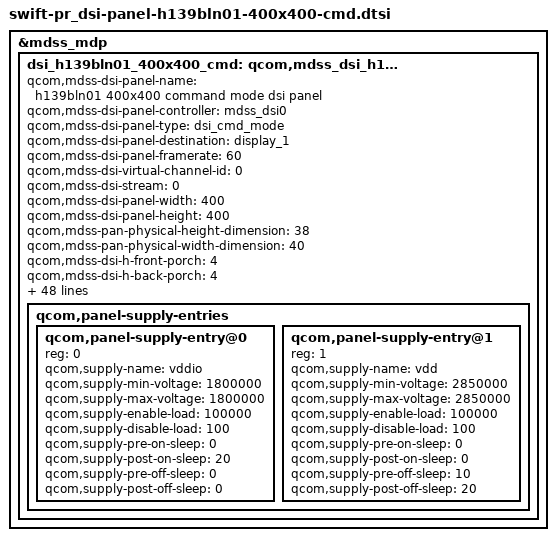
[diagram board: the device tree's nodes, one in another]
/* Copyright (c) 2013-2014, The Linux Foundation. All rights reserved.
 *
 * This program is free software; you can redistribute it and/or modify
 * it under the terms of the GNU General Public License version 2 and
 * only version 2 as published by the Free Software Foundation.
 *
 * This program is distributed in the hope that it will be useful,
 * but WITHOUT ANY WARRANTY; without even the implied warranty of
 * MERCHANTABILITY or FITNESS FOR A PARTICULAR PURPOSE.  See the
 * GNU General Public License for more details.
 */

/*---------------------------------------------------------------------------
 * This file is autogenerated file using gcdb parser. Please do not edit it.
 * Update input XML file to add a new entry or update variable in this file
 * VERSION = "1.0"
 *---------------------------------------------------------------------------*/
&mdss_mdp {
	dsi_h139bln01_400x400_cmd: qcom,mdss_dsi_h139bln01_400_cmd {
		qcom,mdss-dsi-panel-name = "h139bln01 400x400 command mode dsi panel";
		qcom,mdss-dsi-panel-controller = <&mdss_dsi0>;
		qcom,mdss-dsi-panel-type = "dsi_cmd_mode";
		qcom,mdss-dsi-panel-destination = "display_1";
		qcom,mdss-dsi-panel-framerate = <60>;
		qcom,mdss-dsi-virtual-channel-id = <0>;
		qcom,mdss-dsi-stream = <0>;
		qcom,mdss-dsi-panel-width = <400>;
		qcom,mdss-dsi-panel-height = <400>;
		qcom,mdss-pan-physical-height-dimension = <38>;
		qcom,mdss-pan-physical-width-dimension = <40>;

		qcom,mdss-dsi-h-front-porch = <4>;
		qcom,mdss-dsi-h-back-porch = <4>;
		qcom,mdss-dsi-h-pulse-width = <4>;
		qcom,mdss-dsi-h-sync-skew = <0>;
		qcom,mdss-dsi-v-back-porch = <2>;
		qcom,mdss-dsi-v-front-porch = <2>;
		qcom,mdss-dsi-v-pulse-width = <2>;
		qcom,mdss-dsi-h-left-border = <0>;
		qcom,mdss-dsi-h-right-border = <0>;
		qcom,mdss-dsi-v-top-border = <0>;
		qcom,mdss-dsi-v-bottom-border = <0>;
		qcom,mdss-dsi-bpp = <24>;
		qcom,mdss-dsi-underflow-color = <0xff>;
		qcom,mdss-dsi-border-color = <0>;
		qcom,mdss-dsi-on-command = [

			15 01 00 00 00 00 02 FE 00
			15 01 00 00 00 00 02 35 00
			15 01 00 00 00 00 02 53 20
			15 01 00 00 00 00 02 FE 05
			15 01 00 00 00 00 02 05 00
			15 01 00 00 00 00 02 FE 07
			15 01 00 00 00 00 02 07 4F
			15 01 00 00 00 00 02 FE 0A
			15 01 00 00 00 00 02 1C 1B
			15 01 00 00 00 00 02 FE 00
			15 01 00 00 00 00 02 35 00
			05 01 00 00 00 00 02 11 00
			32 01 00 00 00 00 02 00 00
			05 01 00 00 FF 00 02 29 00
			15 01 00 00 00 00 02 51 40

			];

		qcom,mdss-dsi-off-command = [
					05 01 00 00 00 00 02 28 00
					];

		qcom,mdss-dsi-sleep-command = [
			05 01 00 00 78 00 02 10 00
			];

		qcom,mdss-dsi-idle-on-command = [
					05 01 00 00 64 00 02 39 00
					];
		qcom,mdss-dsi-idle-off-command = [
					05 01 00 00 64 00 02 38 00
					];

		//qcom,mdss-dsi-panel-status-command = [06 01 00 01 05 00 02 0A 08];

		qcom,mdss-dsi-idle-command-state = "dsi_lp_mode";

		qcom,mdss-dsi-on-command-state = "dsi_lp_mode";
		qcom,mdss-dsi-off-command-state = "dsi_lp_mode";
		qcom,mdss-dsi-sleep-command-state = "dsi_lp_mode";
		qcom,mdss-dsi-bllp-eof-power-mode;
		qcom,mdss-dsi-bllp-power-mode;
		//qcom,mdss-dsi-lane-map = "lane_map_3012"; /* Eagle's lane map does not need to remap */
		qcom,mdss-dsi-lane-0-state;
		qcom,mdss-dsi-te-pin-select = <1>;
		qcom,mdss-dsi-te-dcs-command = <1>;
		qcom,mdss-dsi-te-check-enable;
		qcom,mdss-dsi-te-using-te-pin;
		qcom,suspend-ulps-enabled;
		qcom,ulps-enabled = <1>;

		/* By AUO's suggestion: MIPI Clock rate = ~290Mbps. */
		qcom,mdss-dsi-panel-timings = [38 0C 08 00 64 64 0C 19 08 03 04 00];

		qcom,mdss-dsi-t-clk-post = <0x04>;
		qcom,mdss-dsi-t-clk-pre = <0x1b>;
		qcom,mdss-dsi-bl-min-level = <1>;
		qcom,mdss-dsi-bl-max-level = <255>;
		qcom,mdss-dsi-dma-trigger = "trigger_sw";
		qcom,mdss-dsi-mdp-trigger = "none";
		qcom,mdss-dsi-bl-pmic-control-type = "bl_ctrl_dcs";
		qcom,mdss-dsi-reset-sequence = <1 20>;

		/* this codebase retrieve panel power from panel node */
		vdd-supply = <&pm8916_l17>;
		vddio-supply = <&pm8916_l15>;
		qcom,panel-supply-entries {
			#address-cells = <1>;
			#size-cells = <0>;

			qcom,panel-supply-entry@0 {
				reg = <0>;
				qcom,supply-name = "vddio";
				qcom,supply-min-voltage = <1800000>;
				qcom,supply-max-voltage = <1800000>;
				qcom,supply-enable-load = <100000>;
				qcom,supply-disable-load = <100>;
				qcom,supply-pre-on-sleep = <0>;
				qcom,supply-post-on-sleep = <20>;
				qcom,supply-pre-off-sleep = <0>;
				qcom,supply-post-off-sleep = <0>;
			};

			qcom,panel-supply-entry@1 {
				reg = <1>;
				qcom,supply-name = "vdd";
				qcom,supply-min-voltage = <2850000>;
				qcom,supply-max-voltage = <2850000>;
				qcom,supply-enable-load = <100000>;
				qcom,supply-disable-load = <100>;
				qcom,supply-pre-on-sleep = <0>;
				qcom,supply-post-on-sleep = <0>;
				qcom,supply-pre-off-sleep = <10>;
				qcom,supply-post-off-sleep = <20>;
			};
		};
	};
};
